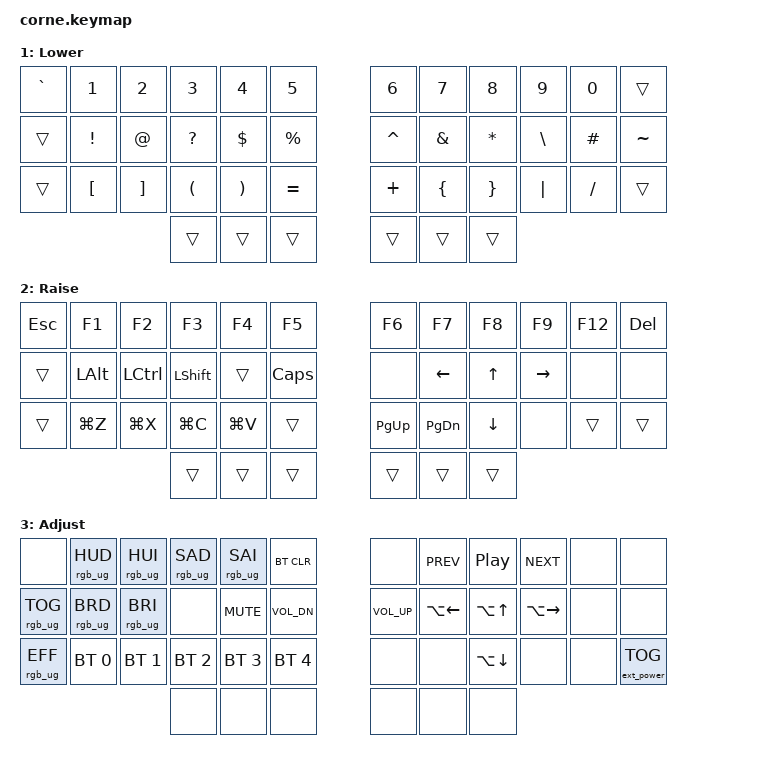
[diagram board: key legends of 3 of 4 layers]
/*
 * Copyright (c) 2020 The ZMK Contributors
 *
 * SPDX-License-Identifier: MIT
 */

#include <behaviors.dtsi>
#include <dt-bindings/zmk/keys.h>
#include <dt-bindings/zmk/bt.h>
#include <dt-bindings/zmk/rgb.h>
#include <dt-bindings/zmk/ext_power.h>

#define BASE 0
#define LOWER 1
#define RAISE 2
#define ADJUST 3

/ {

    behaviors {
        tab_esc: tab_escape {
            compatible = "zmk,behavior-mod-morph";
            #binding-cells = <0>;
            bindings = <&kp ESC>, <&kp TAB>;
            mods = <(MOD_RALT)>;
        };

        tp: tap_preferred {
            compatible = "zmk,behavior-hold-tap";
            label = "TAP_PREFERRED";
            #binding-cells = <2>;
            tapping-term-ms = <250>;
            quick-tap-ms = <0>;
            flavor = "tap-preferred";
            bindings = <&kp>, <&kp>;
          };

        tpm: tap_preferred_mod {
            compatible = "zmk,behavior-hold-tap";
            label = "TAP_PREFERRED_MOD";
            #binding-cells = <2>;
            tapping-term-ms = <140>;
            quick-tap-ms = <0>;
            flavor = "tap-preferred";
            bindings = <&mo>, <&kp>;
          };
    };

    // Activate ADJUST layer by pressing raise and lower
      conditional_layers {
          compatible = "zmk,conditional-layers";
          adjust_layer {
              if-layers = <LOWER RAISE>;
              then-layer = <ADJUST>;
          };
      };

        keymap {
                compatible = "zmk,keymap";

        default_layer {
            display-name = "Dvorak";
// ------------------------------------------------------------------------------------------------------------
// |  TAB  |  '  |  ,  |  .   |  P   |  Y   |                   |  F   |  G    |  C    |  R   |   L   | BKSPC |
// |  CTRL |  A  |  O  |  E   |  U   |  I   |                   |  D   |  H    |  T    |  N   |   S   |   -   |
// | SHIFT |  ;  |  Q  |  J   |  K   |  X   |                   |  B   |  M    |  W    |  V   |   Z   | SHIFT |
//                            | GUI  | LOWER|  ENTER |  | SPACE | RAISE| ALT 
            bindings = <
&tab_esc    &kp SQT   &kp COMMA  &kp DOT   &kp P      &kp Y                                   &kp F      &kp G             &kp C      &kp R      &kp L     &kp BSPC
&kp LCTRL   &kp A     &kp O      &kp E     &kp U      &kp I                                   &kp D      &kp H             &kp T      &kp N      &kp S     &kp MINUS
&kp LSHFT   &kp SEMI  &kp Q      &kp J     &kp K      &kp X                                   &kp B      &kp M             &kp W      &kp V      &kp Z     &kp RSHFT
                                           &kp LGUI   &mo LOWER  &tp LC(LS(LA(LGUI))) RET     &kp SPACE  &tpm RAISE SPACE  &kp RALT   &none      &none
            >;
        };

        lower_layer {
            display-name = "Lower";
// ------------------------------------------------------------------------------------------------------------
// |   `   |  1  |  2  |  3   |  4   |  5   |                   |  6   |  7    |  8    |  9   |   0   |       |
// |       |  !  |  @  |  ?   |  $   |  %   |                   |  ^   |  &    |  *    |  \   |   #   |   ~   |
// |       |  [  |  ]  |  (   |  )   |  =   |                   |  +   |  {    |  }    |  |   |   /   |       |
//               |     |      |      |      |        |  |       |      |       |       |      |
            bindings = <
&kp GRAVE  &kp N1     &kp N2     &kp N3      &kp N4    &kp N5                     &kp N6     &kp N7    &kp N8     &kp N9     &kp N0    &trans
&trans     &kp EXCL   &kp AT     &kp QMARK   &kp DLLR  &kp PRCNT                  &kp CARET  &kp AMPS  &kp ASTRK  &kp BSLH   &kp HASH  &kp TILDE
&trans     &kp LBKT   &kp RBKT   &kp LPAR    &kp RPAR  &kp EQUAL                  &kp PLUS   &kp LBRC  &kp RBRC   &kp PIPE   &kp FSLH  &trans
                                             &trans    &trans     &trans  &trans  &trans     &trans 
            >;
        };

        raise_layer {
            display-name = "Raise";
// ------------------------------------------------------------------------------------------------------------
// |  ESC  | F1   | F2   |  F3   |  F4   |  F5  |                |  F6  |  F7  |  F8   |  F9  |  F10  |  F12  |
// |       | ALT  | CTRL | SHIFT |       | CAPS |                |      |   <- |   ^   |  ->  |       |  DEL  |
// |       | UNDO | CUT  | COPY  | PASTE |      |                | PGUP | PGDN |   v   |      |       |       |
//                |      |       |       |      |      |  |      |      |      |       |      |
            bindings = <
&kp ESC    &kp F1       &kp F2       &kp F3       &kp F4       &kp F5                     &kp F6    &kp F7    &kp F8   &kp F9    &kp F12 &kp DEL
&trans     &kp LALT     &kp LCTRL    &kp LSHFT    &trans       &kp CLCK                   &none     &kp LEFT  &kp UP   &kp RIGHT &none   &none
&trans     &kp LG(Z)   &kp LG(X)     &kp LG(C)    &kp LG(V)    &trans                     &kp PG_UP &kp PG_DN &kp DOWN &none     &trans  &trans
                                                  &trans       &trans     &trans  &trans  &trans    &trans 
            >;
        };

        adjust_layer {
// -----------------------------------------------------------------------------------------------------------------------------
// |        | RGB_HUD | RGB_HUI | RGB_SAD | RGB_SAI | RGB_EFF |                  |      |      |       |      |       |        |
// |        | RGB_BRD | RGB_BRI |         |         |         |                  |      |      |       |      |       |        |
// |        |         |         |         |         |         |                  |      |      |       |      |       | EXTPWR |
//                    |         |         |         |         |         | |      |      |      |       |      |
            display-name = "Adjust";
            bindings = <
&none               &rgb_ug RGB_HUD  &rgb_ug RGB_HUI  &rgb_ug RGB_SAD  &rgb_ug RGB_SAI  &bt BT_CLR                              &none        &kp C_PREV    &kp C_PP     &kp C_NEXT     &none &none
&rgb_ug RGB_TOG     &rgb_ug RGB_BRD  &rgb_ug RGB_BRI  &none            &kp C_MUTE       &kp C_VOL_DN                            &kp C_VOL_UP &kp LA(LEFT)  &kp LA(UP)   &kp LA(RIGHT)  &none &none
&rgb_ug RGB_EFF     &bt BT_SEL 0     &bt BT_SEL 1     &bt BT_SEL 2     &bt BT_SEL 3     &bt BT_SEL 4                            &none        &none         &kp LA(DOWN) &none          &none &ext_power EP_TOG
                                                                       &none            &none            &none           &none  &none        &none
            >;
        };

    };
};
